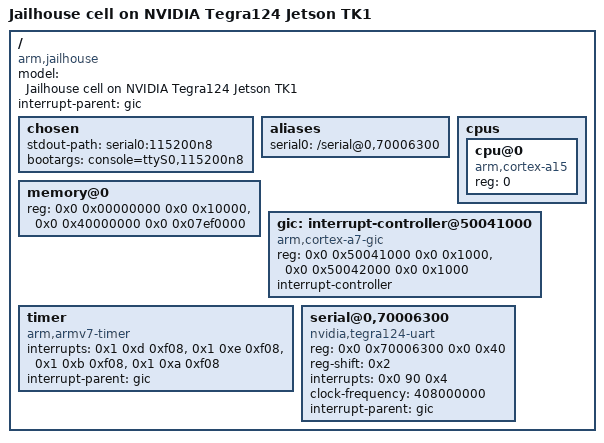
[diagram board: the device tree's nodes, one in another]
/dts-v1/;

/ {
	model = "Jailhouse cell on NVIDIA Tegra124 Jetson TK1";
	compatible = "arm,jailhouse";

	#address-cells = <2>;
	#size-cells = <2>;

	interrupt-parent = <&gic>;

	chosen {
/*		bootargs = "console=jailhouse0 console=tty0";*/
		stdout-path = "serial0:115200n8";
		bootargs = "console=ttyS0,115200n8";

		#address-cells = <2>;
		#size-cells = <2>;
		ranges;
	};

	aliases {
		serial0 = "/serial@0,70006300";
	};

	cpus {
		#address-cells = <1>;
		#size-cells = <0>;

		cpu@0 {
			compatible = "arm,cortex-a15";
			device_type = "cpu";
			reg = <0>;
		};
	};

	memory@0 {
		device_type = "memory";
		reg = <0x0 0x00000000 0x0 0x10000>,
		      <0x0 0x40000000 0x0 0x07ef0000>;
	};

/*	pcie-controller@0,01003000 {
		compatible = "nvidia,tegra124-pcie";
		device_type = "pci";
		reg = <0x0 0x1003000 0x0 0x800 0x0 0x1003800 0x0 0x800 0x0 0x2000000 0x0 0x10000000>;
		reg-names = "pads", "afi", "cs";
		interrupts = <0x0 0x62 0x4 0x0 0x63 0x4>;
		interrupt-names = "intr", "msi";
		#interrupt-cells = <0x1>;
		interrupt-map-mask = <0x0 0x0 0x0 0x0>;
		interrupt-map = <0x0 0x0 0x0 0x0 0x2 0x0 0x62 0x4>;
		bus-range = <0x0 0xff>;
		#address-cells = <0x3>;
		#size-cells = <0x2>;
		ranges = <0x82000000 0x0 0x1000000 0x0 0x1000000 0x0 0x1000 0x82000000 0x0 0x1001000 0x0 0x1001000 0x0 0x1000 0x81000000 0x0 0x0 0x0 0x12000000 0x0 0x10000 0x82000000 0x0 0x13000000 0x0 0x13000000 0x0 0xd000000 0xc2000000 0x0 0x20000000 0x0 0x20000000 0x0 0x20000000>;
		clocks = <0x3 0x46 0x3 0x48 0x3 0xe7 0x3 0x10c>;
		clock-names = "pex", "afi", "pll_e", "cml";
		resets = <0x3 0x46 0x3 0x48 0x3 0x4a>;
		reset-names = "pex", "afi", "pcie_x";
		status = "okay";
		avddio-pex-supply = <0x4>;
		dvddio-pex-supply = <0x4>;
		avdd-pex-pll-supply = <0x4>;
		hvdd-pex-supply = <0x5>;
		hvdd-pex-pll-e-supply = <0x5>;
		vddio-pex-ctl-supply = <0x5>;
		avdd-pll-erefe-supply = <0x6>;

		pci@1,0 {
			device_type = "pci";
			assigned-addresses = <0x82000800 0x0 0x1000000 0x0 0x1000>;
			reg = <0x800 0x0 0x0 0x0 0x0>;
			status = "okay";
			#address-cells = <0x3>;
			#size-cells = <0x2>;
			ranges;
			nvidia,num-lanes = <0x2>;
			phys = <0x7>;
			phy-names = "pcie-0";
		};

		pci@2,0 {
			device_type = "pci";
			assigned-addresses = <0x82001000 0x0 0x1001000 0x0 0x1000>;
			reg = <0x1000 0x0 0x0 0x0 0x0>;
			status = "okay";
			#address-cells = <0x3>;
			#size-cells = <0x2>;
			ranges;
			nvidia,num-lanes = <0x1>;
			phys = <0x8>;
			phy-names = "pcie-0";
		};
	};*/

	gic: interrupt-controller@50041000 {
		compatible = "arm,cortex-a7-gic", "arm,cortex-a15-gic";
		reg = <0x0 0x50041000 0x0 0x1000>,
		      <0x0 0x50042000 0x0 0x1000>;
		interrupt-controller;
		#interrupt-cells = <3>;
	};

	timer {
		compatible = "arm,armv7-timer";
		interrupts = <0x1 0xd 0xf08>,
			     <0x1 0xe 0xf08>,
			     <0x1 0xb 0xf08>,
			     <0x1 0xa 0xf08>;
		interrupt-parent = <&gic>;
	};

	serial@0,70006300 {
		compatible = "nvidia,tegra124-uart", "nvidia,tegra20-uart";
		reg = <0x0 0x70006300 0x0 0x40>;
		reg-shift = <0x2>;
		interrupts = <0x0 90 0x4>;
		clock-frequency = <408000000>;
		status = "okay";
		interrupt-parent = <&gic>;
	};
};
